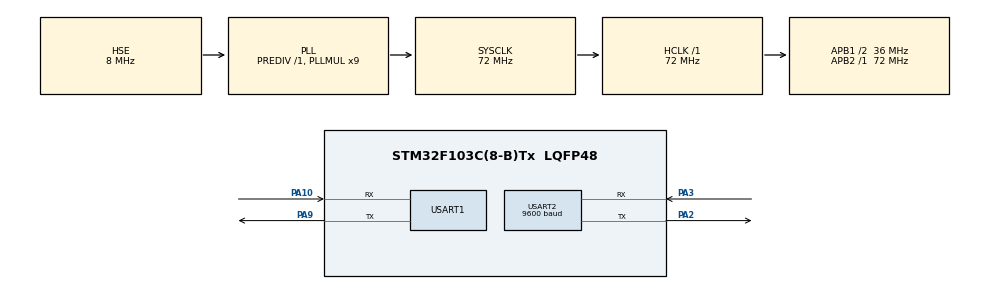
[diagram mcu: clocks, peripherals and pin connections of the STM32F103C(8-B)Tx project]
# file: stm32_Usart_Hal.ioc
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Mcu.Family=STM32F1
RCC.PLLSourceVirtual=RCC_PLLSOURCE_HSE
PD1-OSC_OUT.Mode=HSE-External-Oscillator
PA10.Mode=Asynchronous
PD0-OSC_IN.Signal=RCC_OSC_IN
RCC.APB1CLKDivider=RCC_HCLK_DIV2
NVIC.USART2_IRQn=true\:0\:0\:false\:false\:true\:true\:true
USART2.BaudRate=9600
RCC.SYSCLKSource=RCC_SYSCLKSOURCE_PLLCLK
ProjectManager.StackSize=0x400
PD1-OSC_OUT.Signal=RCC_OSC_OUT
PA13.Signal=SYS_JTMS-SWDIO
PA3.Mode=Asynchronous
PA9.Mode=Asynchronous
ProjectManager.TargetToolchain=MDK-ARM V5.27
RCC.HCLKFreq_Value=72000000
RCC.APB2TimFreq_Value=72000000
PA9.Signal=USART1_TX
RCC.USBFreq_Value=72000000
RCC.AHBFreq_Value=72000000
PD0-OSC_IN.Mode=HSE-External-Oscillator
board=custom
RCC.PLLMUL=RCC_PLL_MUL9
RCC.APB2Freq_Value=72000000
PA14.Mode=Serial_Wire
PA13.Mode=Serial_Wire
Mcu.Name=STM32F103C(8-B)Tx
PA2.Signal=USART2_TX
RCC.SYSCLKFreq_VALUE=72000000
Mcu.Package=LQFP48
USART2.VirtualMode=VM_ASYNC
USART1.VirtualMode=VM_ASYNC
PA10.Signal=USART1_RX
PA14.Signal=SYS_JTCK-SWCLK
ProjectManager.HeapSize=0x200
NVIC.PriorityGroup=NVIC_PRIORITYGROUP_4
RCC.APB1TimFreq_Value=72000000
PA2.Mode=Asynchronous
NVIC.USART1_IRQn=true\:0\:0\:false\:false\:true\:true\:true
RCC.APB1Freq_Value=36000000
PA3.Signal=USART2_RX

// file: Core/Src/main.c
/* USER CODE BEGIN Header */
/**
  ******************************************************************************
  * @file           : main.c
  * @brief          : Main program body
  ******************************************************************************
  * @attention
  *
  * <h2><center>&copy; Copyright (c) 2022 STMicroelectronics.
  * All rights reserved.</center></h2>
  *
  * This software component is licensed by ST under BSD 3-Clause license,
  * the "License"; You may not use this file except in compliance with the
  * License. You may obtain a copy of the License at:
  *                        opensource.org/licenses/BSD-3-Clause
  *
  ******************************************************************************
  */
/* USER CODE END Header */
#include "main.h"

/* USER CODE BEGIN Includes */
#include <string.h>
/* USER CODE END Includes */

UART_HandleTypeDef huart1;
UART_HandleTypeDef huart2;

void SystemClock_Config(void);
static void MX_GPIO_Init(void);
static void MX_USART1_UART_Init(void);
static void MX_USART2_UART_Init(void);

/* USER CODE BEGIN 0 */
char * string1;
/* USER CODE END 0 */

int main(void)
{

  /* MCU Configuration--------------------------------------------------------*/

  /* Reset of all peripherals, Initializes the Flash interface and the Systick. */
  HAL_Init();

  /* Configure the system clock */
  SystemClock_Config();

  /* Initialize all configured peripherals */
  MX_GPIO_Init();
  MX_USART1_UART_Init();
  MX_USART2_UART_Init();
  /* USER CODE BEGIN 2 */
uint8_t Rx_data[10];
  /* USER CODE END 2 */

  /* Infinite loop */
  /* USER CODE BEGIN WHILE */
  while (1)
  {
		HAL_UART_Receive(&huart2,Rx_data,10,100);

		HAL_UART_Transmit(&huart1, Rx_data,10,100);
		//HAL_Delay(1000);

//		HAL_UART_Receive(&huart2,(uint8_t*)string1,strlen(string1),100);
//
//		HAL_UART_Transmit(&huart1, (uint8_t*)string1,strlen(string1),100);
//		HAL_Delay(1000);

    /* USER CODE END WHILE */

  }
}

void SystemClock_Config(void)
{
  RCC_OscInitTypeDef RCC_OscInitStruct = {0};
  RCC_ClkInitTypeDef RCC_ClkInitStruct = {0};

  /** Initializes the RCC Oscillators according to the specified parameters
  * in the RCC_OscInitTypeDef structure.
  */
  RCC_OscInitStruct.OscillatorType = RCC_OSCILLATORTYPE_HSE;
  RCC_OscInitStruct.HSEState = RCC_HSE_ON;
  RCC_OscInitStruct.HSEPredivValue = RCC_HSE_PREDIV_DIV1;
  RCC_OscInitStruct.HSIState = RCC_HSI_ON;
  RCC_OscInitStruct.PLL.PLLState = RCC_PLL_ON;
  RCC_OscInitStruct.PLL.PLLSource = RCC_PLLSOURCE_HSE;
  RCC_OscInitStruct.PLL.PLLMUL = RCC_PLL_MUL9;
  if (HAL_RCC_OscConfig(&RCC_OscInitStruct) != HAL_OK)
  {
    Error_Handler();
  }
  /** Initializes the CPU, AHB and APB buses clocks
  */
  RCC_ClkInitStruct.ClockType = RCC_CLOCKTYPE_HCLK|RCC_CLOCKTYPE_SYSCLK
                              |RCC_CLOCKTYPE_PCLK1|RCC_CLOCKTYPE_PCLK2;
  RCC_ClkInitStruct.SYSCLKSource = RCC_SYSCLKSOURCE_PLLCLK;
  RCC_ClkInitStruct.AHBCLKDivider = RCC_SYSCLK_DIV1;
  RCC_ClkInitStruct.APB1CLKDivider = RCC_HCLK_DIV2;
  RCC_ClkInitStruct.APB2CLKDivider = RCC_HCLK_DIV1;

  if (HAL_RCC_ClockConfig(&RCC_ClkInitStruct, FLASH_LATENCY_2) != HAL_OK)
  {
    Error_Handler();
  }
}

static void MX_USART1_UART_Init(void)
{

  huart1.Instance = USART1;
  huart1.Init.BaudRate = 115200;
  huart1.Init.WordLength = UART_WORDLENGTH_8B;
  huart1.Init.StopBits = UART_STOPBITS_1;
  huart1.Init.Parity = UART_PARITY_NONE;
  huart1.Init.Mode = UART_MODE_TX_RX;
  huart1.Init.HwFlowCtl = UART_HWCONTROL_NONE;
  huart1.Init.OverSampling = UART_OVERSAMPLING_16;
  if (HAL_UART_Init(&huart1) != HAL_OK)
  {
    Error_Handler();
  }

}

static void MX_USART2_UART_Init(void)
{

  huart2.Instance = USART2;
  huart2.Init.BaudRate = 9600;
  huart2.Init.WordLength = UART_WORDLENGTH_8B;
  huart2.Init.StopBits = UART_STOPBITS_1;
  huart2.Init.Parity = UART_PARITY_NONE;
  huart2.Init.Mode = UART_MODE_TX_RX;
  huart2.Init.HwFlowCtl = UART_HWCONTROL_NONE;
  huart2.Init.OverSampling = UART_OVERSAMPLING_16;
  if (HAL_UART_Init(&huart2) != HAL_OK)
  {
    Error_Handler();
  }

}

static void MX_GPIO_Init(void)
{

  /* GPIO Ports Clock Enable */
  __HAL_RCC_GPIOD_CLK_ENABLE();
  __HAL_RCC_GPIOA_CLK_ENABLE();

}

void Error_Handler(void)
{
  __disable_irq();
  while (1)
  {
  }
}

/************************ (C) COPYRIGHT STMicroelectronics *****END OF FILE****/
